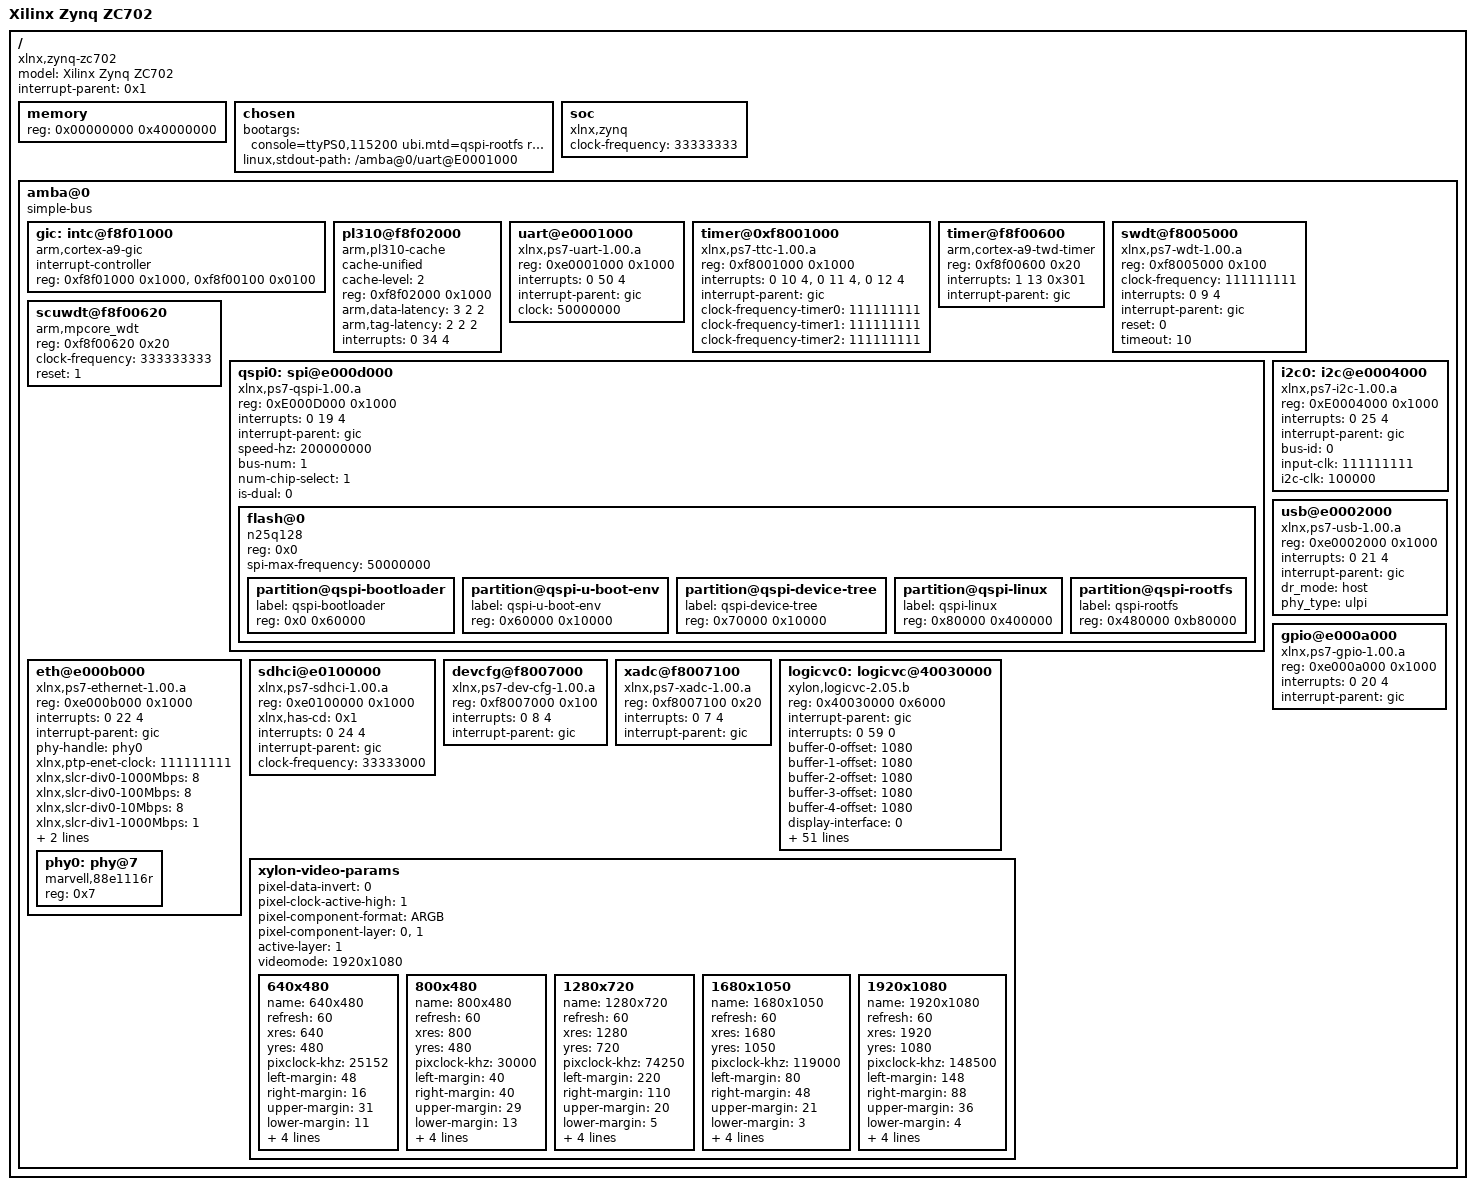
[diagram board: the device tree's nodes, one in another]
/dts-v1/;

/ {
	model = "Xilinx Zynq ZC702";
	compatible = "xlnx,zynq-zc702";
	#address-cells = <0x1>;
	#size-cells = <0x1>;
	interrupt-parent = <0x1>;

	memory {
		device_type = "memory";
		reg = <0x00000000 0x40000000>;
	};
	chosen {
		bootargs = "console=ttyPS0,115200 ubi.mtd=qspi-rootfs root=ubi0:qspi-rootfs rw rootfstype=ubifs rootwait mem=768M memmap=128M$0x30000000 vmalloc=256M";
		linux,stdout-path = "/amba@0/uart@E0001000";
	};

	soc {
		compatible = "xlnx,zynq";
		clock-frequency = <33333333>;
	};

	amba@0 {
		compatible = "simple-bus";
		#address-cells = <0x1>;
		#size-cells = <0x1>;
		ranges;

		gic: intc@f8f01000 {
			interrupt-controller;
			compatible = "arm,cortex-a9-gic";
			#interrupt-cells = <3>;
			reg = < 0xf8f01000 0x1000 >,
			      < 0xf8f00100 0x0100 >;
		};

		pl310@f8f02000 {
			compatible = "arm,pl310-cache";
			cache-unified;
			cache-level = <2>;
			reg = <0xf8f02000 0x1000>;
			arm,data-latency = <3 2 2>;
			arm,tag-latency = <2 2 2>;
			interrupts = <0 34 4>;
		};

		uart@e0001000 {
			compatible = "xlnx,ps7-uart-1.00.a";
			reg = <0xe0001000 0x1000>;
			interrupts = < 0 50 4 >;
			interrupt-parent = <&gic>;
			clock = <50000000>;
		};

		timer@0xf8001000 {
			compatible = "xlnx,ps7-ttc-1.00.a";
			reg = <0xf8001000 0x1000>;
			interrupts = <0 10 4>,<0 11 4>,<0 12 4>;
			interrupt-parent = <&gic>;
			clock-frequency-timer0 = <111111111>;
			clock-frequency-timer1 = <111111111>;
			clock-frequency-timer2 = <111111111>;
		};

		timer@f8f00600 {
			compatible = "arm,cortex-a9-twd-timer";
			reg = <0xf8f00600 0x20>;
			interrupts = <1 13 0x301>;
			interrupt-parent = <&gic>;
		};

		swdt@f8005000 {
			device_type = "watchdog";
			compatible = "xlnx,ps7-wdt-1.00.a";
			reg = <0xf8005000 0x100>;
			clock-frequency = <111111111>;
			interrupts = <0 9 4>;
			interrupt-parent = <&gic>;
			reset = <0>;
			timeout = <10>;
		};

		scuwdt@f8f00620 {
			device_type = "watchdog";
			compatible = "arm,mpcore_wdt";
			reg = <0xf8f00620 0x20>;
			clock-frequency = <333333333>;
			reset = <1>;
		};

		qspi0: spi@e000d000 {
			compatible = "xlnx,ps7-qspi-1.00.a";
			reg = <0xE000D000 0x1000>;
			interrupts = <0 19 4>;
			interrupt-parent = <&gic>;
			speed-hz = <200000000>;
			bus-num = <1>;
			num-chip-select = <1>;
			#address-cells = <1>;
			#size-cells = <0>;
			is-dual = <0>;
			flash@0 {
			compatible = "n25q128";
			reg = <0x0>;
			spi-max-frequency = <50000000>;
			#address-cells = <1>;
			#size-cells = <1>;
			partition@qspi-bootloader {
				label = "qspi-bootloader";
				reg = <0x0 0x60000>;
				};
			partition@qspi-u-boot-env {
				label = "qspi-u-boot-env";
				reg = <0x60000 0x10000>;
				};
			partition@qspi-device-tree {
				label = "qspi-device-tree";
				reg = <0x70000 0x10000>;
				};
			partition@qspi-linux {
				label = "qspi-linux";
				reg = <0x80000 0x400000>;
				};
			partition@qspi-rootfs {
				label = "qspi-rootfs";
				reg = <0x480000 0xb80000>;
				};
			};
		};

		eth@e000b000 {
			compatible = "xlnx,ps7-ethernet-1.00.a";
			reg = <0xe000b000 0x1000>;
			interrupts = <0 22 4>;
			interrupt-parent = <&gic>;
			phy-handle = <&phy0>;
			xlnx,ptp-enet-clock = <111111111>;
			xlnx,slcr-div0-1000Mbps = <8>;
			xlnx,slcr-div0-100Mbps = <8>;
			xlnx,slcr-div0-10Mbps = <8>;
			xlnx,slcr-div1-1000Mbps = <1>;
			xlnx,slcr-div1-100Mbps = <5>;
			xlnx,slcr-div1-10Mbps = <50>;
			#address-cells = <0x1>;
			#size-cells = <0x0>;

			phy0: phy@7 {
				compatible = "marvell,88e1116r";
				device_type = "ethernet-phy";
				reg = <0x7>;
			};
		};

		i2c0: i2c@e0004000 {
			compatible = "xlnx,ps7-i2c-1.00.a";
			reg = <0xE0004000 0x1000>;
			interrupts = <0 25 4>;
			interrupt-parent = <&gic>;
			bus-id = <0>;
			input-clk = <111111111>;
			i2c-clk = <100000>;

			#address-cells = <1>;
			#size-cells = <0>;
		};

		sdhci@e0100000 {
			compatible = "xlnx,ps7-sdhci-1.00.a";
			reg = <0xe0100000 0x1000>;
			xlnx,has-cd = <0x1>;
			interrupts = <0 24 4>;
			interrupt-parent = <&gic>;
			clock-frequency = <33333000>;
		};

		usb@e0002000 {
			compatible = "xlnx,ps7-usb-1.00.a";
			reg = <0xe0002000 0x1000>;
			interrupts = <0 21 4>;
			interrupt-parent = <&gic>;
			dr_mode = "host";
			phy_type = "ulpi";
		};

		gpio@e000a000 {
			compatible = "xlnx,ps7-gpio-1.00.a";
			reg = <0xe000a000 0x1000>;
			interrupts = <0 20 4>;
			interrupt-parent = <&gic>;
		};

		devcfg@f8007000 {
			compatible = "xlnx,ps7-dev-cfg-1.00.a";
			reg = <0xf8007000 0x100>;
			interrupts = <0 8 4>;
			interrupt-parent = <&gic>;
		};
		xadc@f8007100 {
			compatible = "xlnx,ps7-xadc-1.00.a";
			reg = <0xf8007100 0x20>;
			interrupts = <0 7 4>;
			interrupt-parent = <&gic>;
		};

		logicvc0: logicvc@40030000 {
			compatible = "xylon,logicvc-2.05.b", "xylon,logicvc-2.05.c";
			reg = <0x40030000 0x6000>;
			interrupt-parent = <&gic>;
			interrupts = < 0 59 0 >;
			buffer-0-offset = <1080>;
			buffer-1-offset = <1080>;
			buffer-2-offset = <1080>;
			buffer-3-offset = <1080>;
			buffer-4-offset = <1080>;
			display-interface = <0>;
			e-data-width = <24>;
			e-layer = <0>;
			interconnect-m-axi-arb-priority = <0xf>;
			ip-license-type = <0>;
			ip-major-revision = <2>;
			ip-minor-revision = <5>;
			ip-patch-level = <0>;
			layer-0-alpha-mode = <0>;
			layer-0-data-width = <16>;
			layer-0-offset = <0x0>;
			layer-1-alpha-mode = <0>;
			layer-1-data-width = <24>;
			layer-1-offset = <3240>;
			layer-2-alpha-mode = <0>;
			layer-2-data-width = <24>;
			layer-2-offset = <6480>;
			layer-3-alpha-mode = <0>;
			layer-3-data-width = <24>;
			layer-3-offset = <9720>;
			layer-4-alpha-mode = <0>;
			layer-4-data-width = <24>;
			layer-4-offset = <12960>;
			little-endian = <1>;
			lvds-data-width = <4>;
			mem-burst = <4>;
			mplb-awidth = <32>;
			mplb-dwidth = <64>;
			mplb-native-dwidth = <32>;
			mplb-num-masters = <8>;
			mplb-p2p = <0>;
			mplb-priority = <3>;
			mplb-smallest-slave = <32>;
			mplb-support-bursts = <1>;
			num-of-layers = <3>;
			pixel-data-width = <24>;
			readable-regs = <1>;
			regs-interface = <2>;
			regs-little-endian = <1>;
			row-stride = < 2048 >;
			use-background = <0>;
			use-e-rgb-input = <0>;
			use-e-vclk-bufgmux = <1>;
			use-io-hw-serializer = <0>;
			use-multiplier = <2>;
			use-serialized-blender = <0>;
			use-size-position = < 1 >;
			use-xtreme-dsp = <2>;
			vmem-baseaddr = <0x30000000>;
			vmem-highaddr = <0x37ffffff>;
			vmem-data-bus-width = <64>;
			vmem-interface = <2>;
		};

		xylon-video-params {
			pixel-data-invert = <0>;
			pixel-clock-active-high = <1>;
			pixel-component-format = "ARGB";
			pixel-component-layer = <0>,<1>;
			active-layer = <1>;
			videomode = "1920x1080";
			640x480 {
				name = "640x480";
				refresh = <60>;
				xres = <640>;
				yres = <480>;
				pixclock-khz = <25152>;
				left-margin = <48>;
				right-margin = <16>;
				upper-margin = <31>;
				lower-margin = <11>;
				hsync-len = <96>;
				vsync-len = <2>;
				sync = <0>;
				vmode = <0>;
			};
			800x480 {
				name = "800x480";
				refresh = <60>;
				xres = <800>;
				yres = <480>;
				pixclock-khz = <30000>;
				left-margin = <40>;
				right-margin = <40>;
				upper-margin = <29>;
				lower-margin = <13>;
				hsync-len = <48>;
				vsync-len = <3>;
				sync = <0>;
				vmode = <0>;
			};
			1280x720 {
				name = "1280x720";
				refresh = <60>;
				xres = <1280>;
				yres = <720>;
				pixclock-khz = <74250>;
				left-margin = <220>;
				right-margin = <110>;
				upper-margin = <20>;
				lower-margin = <5>;
				hsync-len = <40>;
				vsync-len = <5>;
				sync = <0>;
				vmode = <0>;
			};
			1680x1050 {
				name = "1680x1050";
				refresh = <60>;
				xres = <1680>;
				yres = <1050>;
				pixclock-khz = <119000>;
				left-margin = <80>;
				right-margin = <48>;
				upper-margin = <21>;
				lower-margin = <3>;
				hsync-len = <32>;
				vsync-len = <6>;
				sync = <0>;
				vmode = <0>;
			};
			1920x1080 {
				name = "1920x1080";
				refresh = <60>;
				xres = <1920>;
				yres = <1080>;
				pixclock-khz = <148500>;
				left-margin = <148>;
				right-margin = <88>;
				upper-margin = <36>;
				lower-margin = <4>;
				hsync-len = <44>;
				vsync-len = <5>;
				sync = <0>;
				vmode = <0>;
			};
		};
	};
};
